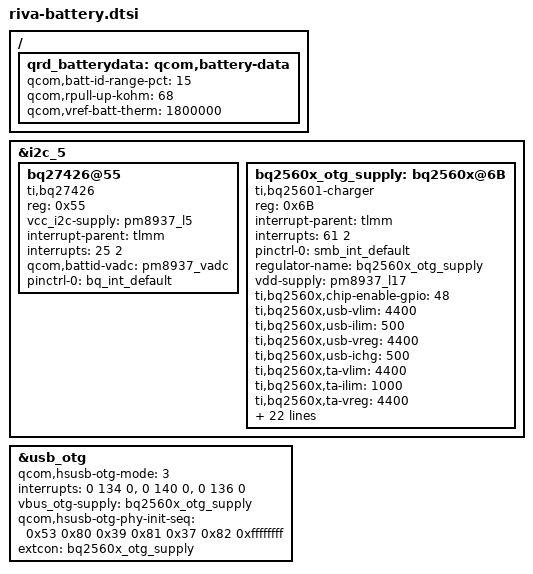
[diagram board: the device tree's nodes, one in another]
/*
 * Copyright (c) 2016, The Linux Foundation. All rights reserved.
 * Copyright (C) 2018 XiaoMi, Inc.
 *
 * This program is free software; you can redistribute it and/or modify
 * it under the terms of the GNU General Public License version 2 and
 * only version 2 as published by the Free Software Foundation.
 *
 * This program is distributed in the hope that it will be useful,
 * but WITHOUT ANY WARRANTY; without even the implied warranty of
 * MERCHANTABILITY or FITNESS FOR A PARTICULAR PURPOSE.  See the
 * GNU General Public License for more details.
 */

&i2c_5 {
	status = "ok";

	bq27426@55 {
		compatible = "ti,bq27426";
		reg = <0x55>;

		vcc_i2c-supply = <&pm8937_l5>;
		interrupt-parent = <&tlmm>;
		interrupts = <25 2>;
		qcom,battid-vadc = <&pm8937_vadc>;
		pinctrl-names = "default";
		pinctrl-0 = <&bq_int_default>;
	};

	bq2560x_otg_supply: bq2560x@6B {
		compatible = "ti,bq25601-charger";
		reg = <0x6B>;
		interrupt-parent = <&tlmm>;
		interrupts = <61 2>;
		pinctrl-names = "default";
		pinctrl-0 = <&smb_int_default>;

		regulator-name = "bq2560x_otg_supply";
		vdd-supply = <&pm8937_l17>;

		ti,bq2560x,chip-enable-gpio = <48>;
		ti,bq2560x,usb-vlim = <4400>;
		ti,bq2560x,usb-ilim = <500>;
		ti,bq2560x,usb-vreg = <4400>;
		ti,bq2560x,usb-ichg = <500>;

		ti,bq2560x,ta-vlim = <4400>;
		ti,bq2560x,ta-ilim = <1000>;
		ti,bq2560x,ta-vreg = <4400>;
		ti,bq2560x,ta-ichg = <1500>;
		qcom,thermal-mitigation = <1000 800 700 0>;

		ti,bq2560x,precharge-current = <256>;
		ti,bq2560x,termination-current = <60>;
		ti,bq2560x,boost-voltage = <4998>;
		ti,bq2560x,boost-current = <500>;
		ti,bq2560x,enable_term;
		ti,bq2560x,stat-pin-ctrl = <0>;
		ti,bq2560x,vac-ovp-threshold = <6500>;

		ti,bq2560x,jeita-hot-degc = <550>;
		ti,bq2560x,jeita-warm-degc = <450>;
		ti,bq2560x,jeita-cool-normal-degc = <150>;
		ti,bq2560x,jeita-cold-cool-degc = <50>;
		ti,bq2560x,jeita-cold-degc = <0>;

		ti,bq2560x,jeita-hot-hysteresis = <20>;
		ti,bq2560x,jeita-cold-hysteresis = <10>;

		ti,bq2560x,jeita-cold-cool-ma = <300>;
		ti,bq2560x,jeita-cool-normal-ma = <600>;
		ti,bq2560x,jeita-cool-mv = <4400>;
		ti,bq2560x,jeita-warm-ma = <1000>;
		ti,bq2560x,jeita-warm-mv = <4100>;

		ti,bq2560x,software-jeita-supported;
	};
};

&usb_otg {
	qcom,hsusb-otg-mode = <3>;
	interrupts = <0 134 0>,<0 140 0>,<0 136 0>;
	interrupt-names = "core_irq", "async_irq", "phy_irq";
	vbus_otg-supply = <&bq2560x_otg_supply>;
	qcom,hsusb-otg-phy-init-seq =
		<0x53 0x80 0x39 0x81 0x37 0x82 0xffffffff>;

	extcon = <&bq2560x_otg_supply>;
};

/ {
	qrd_batterydata: qcom,battery-data {
			qcom,batt-id-range-pct = <15>;
			qcom,rpull-up-kohm = <68>;
			qcom,vref-batt-therm = <1800000>;
			#include "../../../batterydata-qrd-sku2-4v35-2590mah.dtsi"
			#include "battery/batterydata-wingtech-desai_SAMSUNG-4v4-4000mah.dtsi"
			#include "battery/batterydata-wingtech-feimaotui_SONY-4v4-4000mah.dtsi"
			#include "battery/batterydata-wingtech-xingwangda_ATL-4v4-4000mah.dtsi"
			#include "battery/batterydata-wingtech-guangyu_Coslight-4v4-4000mah.dtsi"
	};

};
